# Supply_Voltage_Supervisor_2 register map
Vendor: Texas Instruments
Peripheral module from a debugger description file (folder msp430).
Registers are 8-bit, read-write, reset 0x0 unless marked. A register's access mark holds for its fields unless they carry their own. Offsets are as the file gives them; lines under a group give offsets from that group; [hi:lo] are bit positions; {n}, {i} and the like mark numbered series; 'fields as' and 'values as' point back to an identical list; <NAME> marks a mode.

## Supply_Voltage_Supervisor
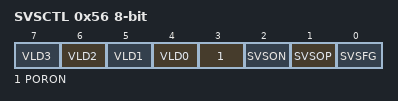
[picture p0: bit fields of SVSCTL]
0x56 SVSCTL — SVS Control
  [n+4] VLD{n} (n=0..3)
  [3] PORON — Enable POR Generation if Low Voltage
  [2] SVSON — Switches the SVS on/off
  [1] SVSOP — SVS output (read only)
  [0] SVSFG — SVS Flag
